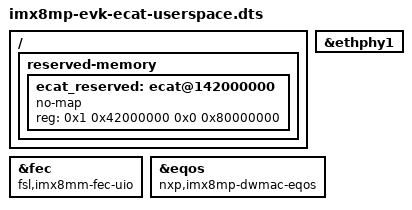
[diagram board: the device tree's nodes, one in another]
// SPDX-License-Identifier: GPL-2.0+
/*
 * Copyright 2024 NXP
 */

#include "imx8mp-evk.dts"

/{
       reserved-memory {
               #address-cells = <2>;
               #size-cells = <2>;
               ranges;
	       /* Limit memory in 4G Bytes for user space EtherCAT */
       	       ecat_reserved: ecat@142000000 {
       	               no-map;
       	               reg = <0x1 0x42000000 0x0 0x80000000>;
       	       };
       };
};

&ethphy1 {
	/delete-property/ reset-gpios;
	/delete-property/ reset-assert-us;
	/delete-property/ reset-deassert-us;
};

&fec {
	compatible = "fsl,imx8mm-fec-uio";
};

&eqos {
	compatible = "nxp,imx8mp-dwmac-eqos","snps,dwmac-5.10a";
};
